# MSPM0G511X register map
Vendor: Texas Instruments; File version: Revised: 2025-07-22 15:38:34
CPU: CM0 r0p1, little endian, MPU, no FPU, 3 interrupt priority bits
Registers are 32-bit, read-write, reset 0x0 unless marked. A register's access mark holds for its fields unless they carry their own. Offsets are from the block's base; [hi:lo] are bit positions; lines under a group give offsets from that group; {n}, {i} and the like mark numbered series; 'fields as' and 'values as' point back to an identical list.

## IOMUX — PERIPHERALREGION
Base 0x40428000
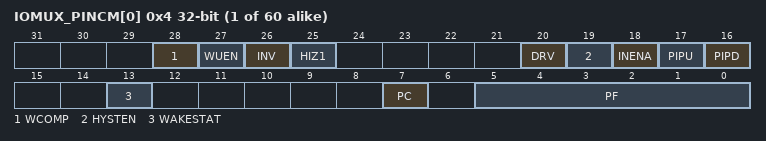
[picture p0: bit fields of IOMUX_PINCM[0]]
{0x4+4i} IOMUX_PINCM[{i}] (i=0..59) — Pin Control Management Register in SECCFG region
  [28] WCOMP — Wakeup Compare Value bit
    0=MATCH0 (Wakeup on a match of 0); 1=MATCH1 (Wakeup on a match of 1)
  [27] WUEN — Wakeup Enable bit
    0=DISABLE (wakeup is disabled.); 1=ENABLE (wakeup is enabled)
  [26] INV — Data inversion selection
    0=DISABLE (Data inversion is disabled.); 1=ENABLE (Data inversion is enabled)
  [25] HIZ1 — High output value will tri-state the output when this bit is enabled
    0=DISABLE (open-drain is disabled.); 1=ENABLE (open-drain is enabled.)
  [20] DRV — Drive strength control selection, for HS IOCELL only
    0=DRVVAL0 (Drive setting of 0 selected); 1=DRVVAL1 (Drive setting of 1 selected)
  [19] HYSTEN — Hysteresis Enable Control Selection
    0=DISABLE (hysteresis is disabled.); 1=ENABLE (hysteresis is enabled)
  [18] INENA — Input Enable Control Selection
    0=DISABLE (Input enable is disabled.); 1=ENABLE (Input enable is enabled.)
  [17] PIPU — Pull Up control selection
    0=DISABLE (Pull up is disabled.); 1=ENABLE (Pull up is enabled)
  [16] PIPD — Pull Down control selection
    0=DISABLE (Pull down is disabled.); 1=ENABLE (Pull down is enabled)
  [13] WAKESTAT ro — This has the IOPAD WAKEUP signal as status bit.
    0=DISABLE (wakeup source is NOT from this IOCELL); 1=ENABLE (wakeup source is from this IOCELL)
  [7] PC — Peripheral is Connected
    0=UNCONNECTED (The output of the peripheral (and its output enable) will not propagate to the IOCELL); 1=CONNECTED (The output latch of the dataflow will be transparent)
  [5:0] PF — Peripheral Function selection bits

## UC2 — PERIPHERALREGION
Base 0x40B80000
{0x800+0x18*i} UC2_GPRCM[{i}] (i=0..0) group
  0x00 UC2_PWREN — Power enable
    [0] ENABLE — Enable the power
      0=DISABLE (Disable Power); 1=ENABLE (Enable Power)
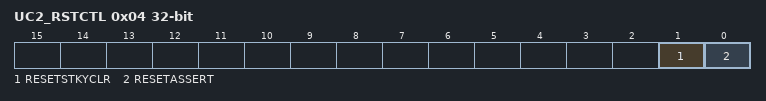
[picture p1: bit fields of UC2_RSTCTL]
  0x04 UC2_RSTCTL wo — Reset Control
    [1] RESETSTKYCLR — Clear the RESETSTKY bit in the STAT register
      0=NOP (Writing 0 has no effect); 1=CLR (Clear reset sticky bit)
    [0] RESETASSERT — Assert reset to the peripheral
      0=NOP (Writing 0 has no effect); 1=ASSERT (Assert reset)
  0x08 UC2_CLKCFG — Peripheral Clock Configuration Register
    [8] BLOCKASYNC — Async Clock Request is blocked from starting SYSOSC or forcing bus clock to 32MHz
      0=DISABLE (Not block async clock request); 1=ENABLE (Block async clock request)
  0x14 UC2_GPRCM_STAT ro — Status Register
    [16] RESETSTKY — This bit indicates, if the peripheral was reset, since this bit was cleared by RESETSTKYCLR in the RSTCTL register
      0=NORES (The peripheral has not been reset since this bit was last cleared by RESETSTKYCLR in the RSTCTL register); 1=RESET (The peripheral was reset since the last bit clear)

## UC3 — PERIPHERALREGION
Base 0x40B82000
Registers as UC2 (with UC2 read as UC3); these are added or differ:
0x1100 UC3_IPMODE — Mode Selection Register
  [1:0] SELECT — Free run control
    0=UART (Default functionality is UART); 1=SPI (SPG in SPI Mode); 2=I2C_CONTROLLER (SPG in I2C Controller Mode); 3=I2C_PERIPHERAL (SPG in I2C Peripheral Mode)

## UC0 — PERIPHERALREGION
Base 0x40A80000
Registers as UC3 (with UC3 read as UC0).

## UC1 — PERIPHERALREGION
Base 0x40A82000
Registers as UC3 (with UC3 read as UC1).

## ADC0_SVT — PERIPHERALREGIONSVT
Base 0x4055A000
0x556160 ADC0_FIFODATA ro — FIFO Data Register
{0x556280+4i} ADC0_MEMRES[{i}] (i=0..11) ro — Memory Result Register
  [15:0] DATA — MEMRES result register. If DF = 0, unsigned binary: The conversion results are right aligned. In 10 and 8 bit modes, the unused MSB bits are forced to 0. If DF = 1, 2s-complement format: The conversion results are left aligned. In 10 and 8 bit modes, the unused LSB bits are forced to 0. The data is stored in the right-justified format and is converted to the left-justified 2s-complement format during read back.

## SPG0 — PERIPHERALREGION
Base 0x40A9F000
{0x1120+4i} SPG0_UNICOMM_LPBK[{i}] (i=0..0) group
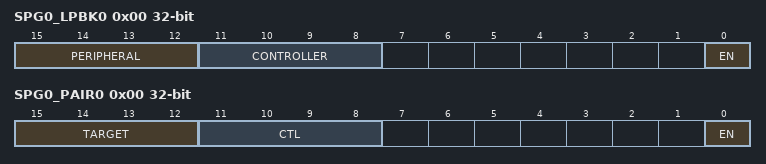
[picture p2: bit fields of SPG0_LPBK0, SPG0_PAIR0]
  0x00 SPG0_LPBK0 — Loopback between SPG instances User has to ensure that the SPGs looped back have the same underlying IP instantiated; i.e. both UART, both SPI, both I2C, etc.,
    [15:12] PERIPHERAL — Select SPG peripheral for loopback. Signals invovled in loopback based on interface chosen 1. SPI : CS, SCLK, SDI, SDO 2. I2C : SCL, SDA 3. UART : TX, RX
      {v}=SPG{v+1} (SPG responder select for loopback.) (v=0..15)
    [11:8] CONTROLLER — Select SPG controller for loopback. Signals invovled in loopback based on interface chosen 1. SPI : CS, SCLK, SDI, SDO 2. I2C : SCL, SDA 3. UART : TX, RX
      {v}=SPG{v+1} (SPG commander select for loopback.) (v=0..15)
    [0] EN — Loopback enable
      0=DISABLE (Does not select this clock as a source); 1=ENABLE (Select this clock as a source)
{0x11C0+4i} SPG0_I2C_PAIR[{i}] (i=0..0) group
  0x00 SPG0_PAIR0 — Pairing of I2C for MULTI-MASTER/SMBUS applications
    [15:12] TARGET — UNICOMM instance for loopback. This instance will be treated as the target
      {v}=SPG{v+1} (SPG responder select for loopback.) (v=0..15)
    [11:8] CTL — UNICOMM instance for loopback. This instance will be treated as the controller.
      {v}=SPG{v+1} (SPG commander select for loopback.) (v=0..15)
    [0] EN — Enable
      values as SPG0_UNICOMM_LPBK[0].SPG0_LPBK0.EN
